# AC7842x register map
Vendor: AutoChips; Series: AC78; File version: 1.0
CPU: CM4 r0p1, little endian, MPU, FPU, VTOR, 4 interrupt priority bits
Registers are 32-bit, read-write, reset 0x0 unless marked. A register's access mark holds for its fields unless they carry their own. Offsets are from the block's base; [hi:lo] are bit positions; {n}, {i} and the like mark numbered series.

## SENT_CTRL — SENT Module Control
Base 0x40010000
0x00 FDR — Fractional Divider Regitser
  [9:0] STEP — Module frequency divided by STEP
0x04 CTS ro — Current Time Stamp
  [31:0] CTS — Module Timestamp, writing TDIV will clear value and restart counting
0x08 TDIV — Timestamp Pre Divider Register
  [19:0] TDIV — Module frequency divided by (TDIV+1)

## TIMER_CTRL — Timer Control
Base 0x40011000
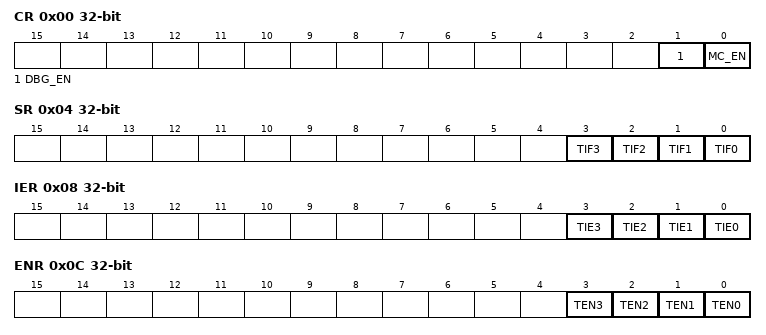
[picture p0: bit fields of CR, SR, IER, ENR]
0x00 CR — Timer Control Regitser
  [1] DBG_EN — Timer Debug Mode Enable
    0=Stop timer channels in Debug mode; 1=Allow timer channels to continue to run in Debug mode
  [0] MC_EN — Module Clock Enable
    0=Disable Module Clock; 1=Enable Module Clock
0x04 SR — Timer Status Regitser
  [n] TIF{n} (n=0..3) — Channel {n} Timer Interrupt Flag
    0=Timer{n} interrupt has not occurred; 1=Timer{n} interrupt has occurred
0x08 IER — TIMER Interrupt Enable Register
  [n] TIE{n} (n=0..3) — Channel {n} Timer Interrupt Enable
    0=Channel {n} Timer interrupt disabled; 1=Channel {n} Timer interrupt enabled
0x0C ENR — TIMER Enable Register
  [n] TEN{n} (n=0..3) — Channel {n} Timer Enable bit
    0=Channel {n} Timer disabled; 1=Channel {n} Timer enabled

## TIMER_CHANNEL0
Base 0x40011010
Same registers: TIMER_CHANNEL1 0x40011020, TIMER_CHANNEL2 0x40011030, TIMER_CHANNEL3 0x40011040
0x00 TVAL — Timer Load Value Register
  [31:0] TVAL — Timer Load Value
0x04 CVAL — Timer Current Count Value Register
  [31:0] CVAL — Timer Current Count Value
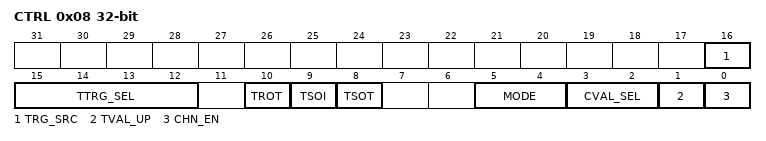
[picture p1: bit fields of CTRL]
0x08 CTRL — Timer channel Control Register
  [16] TRG_SRC — Timer channel Trigger source
    0=Selects external triggers; 1=Selects internal triggers
  [15:12] TTRG_SEL — Timer internal Trigger select
    {v}=trigger source {v} select (v=0..3)
  [10] TROT — Timer Reload On Trigger
    0=Timer will not reload on the selected trigger; 1=Timer will reload on the selected trigger
  [9] TSOI — Timer Stop On Interrupt
    0=The channel timer does not stop after timeout; 1=The channel timer will stop after a timeout
  [8] TSOT — Timer Start On Trigger
    0=Timer starts to increment immediately based on the restart condition(TSOI); 1=Timer starts to increment when a trigger is detected
  [5:4] MODE — Timer Operation Mode
    0=32-bit Periodic Counter; 1=Dual 16-bit Periodic Counter; 2=32-bit Trigger Accumulator; 3=32-bit Trigger Input Capture
  [3:2] CVAL_SEL — Read CVAL precision selection
    0=When BUSCLK/FUNCLK greater than 4; 1=When BUSCLK/FUNCLK greater than 3; 2=When BUSCLK/FUNCLK greater than 1
  [1] TVAL_UP — Timer value update selection
    0=When write,timer value will take effect on timeout occured; 1=When write,timer value will take effect immediately
  [0] CHN_EN — Timer Channel Chain Enable
    0=channel chain is disabled; 1=channel chain is enabled

## PCT — Pulse Count Timer
Base 0x40019000
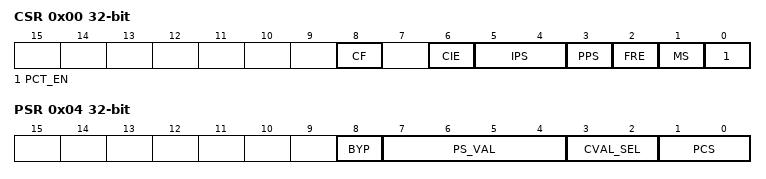
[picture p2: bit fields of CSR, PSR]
0x00 CSR — PCT Control Status Register
  [8] CF — compare flag
    0=The value of CNR is not equal to CMR and increments; 1=The value of CNR is equal to CMR and increments
  [6] CIE — Compare interrupt enable
    0=Compare interrupt is disabled; 1=Compare interrupt is enabled
  [5:4] IPS — PCT input pin select
    {v}=Pulse counter input {v} is selected (v=0..3)
  [3] PPS — Pin Polarity select
    0=Pulse is active-high, and CNR will increment on rising-edge; 1=Pulse is active-low, and CNR will increment on falling-edge
  [2] FRE — Free-running enable
    0=CNR is reset whenever compare flag is set; 1=CNR is reset on overflow
  [1] MS — PCT Mode Select
    0=Time counter mode; 1=Pulse counter mode
  [0] PCT_EN — PCT Enable
    0=PCT is disabled; 1=PCT is enabled
0x04 PSR — PCT prescaler Register
  [8] BYP — Bypass enable
    0=Prescaler/glitch filter is enabled; 1=Prescaler/glitch filter is bypassed
  [7:4] PS_VAL — Prescaler Value
    0=prescaler by 2,glitch filter does not support this configuration; 1=Prescaler by 4,glitch filter after 2 edges; 2=Prescaler by 8,glitch filter after 4 edges; 3=Prescaler by 16,glitch filter after 8 edges; 4=Prescaler by 32,glitch filter after 16 edges; 5=Prescaler by 64,glitch filter after 32 edges; 6=Prescaler by 128,glitch filter after 64 edges; 7=Prescaler by 256,glitch filter after 128 edges; 8=Prescaler by 512,glitch filter after 256 edges; 9=Prescaler by 1024,glitch filter after 512 edges; 10=Prescaler by 2048,glitch filter after 1024 edges; 11=Prescaler by 4096,glitch filter after 2048 edges; 12=Prescaler by 8192,glitch filter after 4096 edges; 13=Prescaler by 16384,glitch filter after 8192 edges; 14=Prescaler by 32768,glitch filter after 16384 edges; 15=Prescaler by 65536,glitch filter after 32768 edges
  [3:2] CVAL_SEL — Read CVAL precision selection
    0=When BUSCLK/FUNCLK greater than 4; 1=When BUSCLK/FUNCLK greater than 3; 2=When BUSCLK/FUNCLK greater than 1
  [1:0] PCS — Prescaler Clock Select
    {v}=Prescaler/glitch filter clock {v} selected (v=0..3)
0x08 CMR — PCT Compare Register
  [15:0] CMR — PCT compare Value
0x0C CNR — PCT Counter Register
  [15:0] CNR — PCT Counter Value
